# STM32WLE5_CM4 register map
File version: 1.0
CPU: CM4 r0p1, little endian, MPU, FPU, 4 interrupt priority bits
Registers are 32-bit, read-write, reset 0x0 unless marked. A register's access mark holds for its fields unless they carry their own. Offsets are from the block's base; [hi:lo] are bit positions; {n}, {i} and the like mark numbered series.

## VREFBUF — Voltage reference buffer
Base 0x40010030
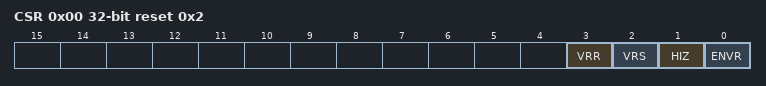
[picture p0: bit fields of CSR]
0x00 CSR access per field reset 0x2 — control and status register
  [3] VRR ro — Voltage reference buffer ready
  [2] VRS rw — Voltage reference scale
  [1] HIZ rw — High impedance mode
  [0] ENVR rw — Voltage reference buffer mode enable
0x04 CCR — calibration control register
  [5:0] TRIM — Trimming code

## IWDG — Independent watchdog
Base 0x40003000
0x00 KR wo — Key register
  [15:0] KEY — Key value (write only, read 0x0000)
0x04 PR reset 0x7 — Prescaler register
  [2:0] PR — Prescaler divider
0x08 RLR reset 0xFFF — Reload register
  [11:0] RL — Watchdog counter reload value
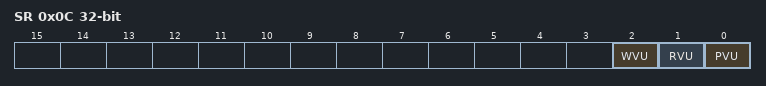
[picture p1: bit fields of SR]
0x0C SR ro — Status register
  [2] WVU — Watchdog counter window value update
  [1] RVU — Watchdog counter reload value update
  [0] PVU — Watchdog prescaler value update
0x10 WINR reset 0xFFF — Window register
  [11:0] WIN — Watchdog counter window value

## WWDG — System window watchdog
Base 0x40002C00
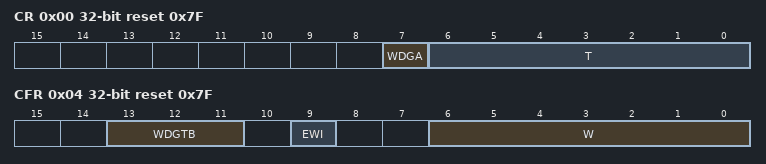
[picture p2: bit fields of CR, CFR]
0x00 CR reset 0x7F — Control register
  [7] WDGA — Activation bit
  [6:0] T — 7-bit counter (MSB to LSB)
0x04 CFR access per field reset 0x7F — Configuration register
  [13:11] WDGTB rw — Timer base
  [9] EWI wo — Early wakeup interrupt
  [6:0] W rw — 7-bit window value
0x08 SR — Status register
  [0] EWIF — Early wakeup interrupt flag

## AES — Advanced encryption standard hardware accelerator 1
Base 0x58001800
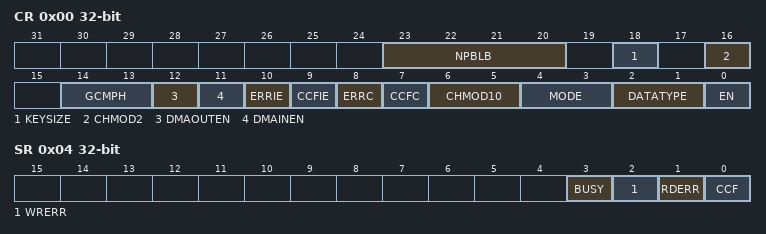
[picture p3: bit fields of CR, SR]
0x00 CR — control register
  [23:20] NPBLB — Number of padding bytes in last block of payload
  [18] KEYSIZE — Key size selection
  [16] CHMOD2 — AES chaining mode Bit2
  [14:13] GCMPH — Used only for GCM, CCM and GMAC algorithms and has no effect when other algorithms are selected
  [12] DMAOUTEN — Enable DMA management of data output phase
  [11] DMAINEN — Enable DMA management of data input phase
  [10] ERRIE — Error interrupt enable
  [9] CCFIE — CCF flag interrupt enable
  [8] ERRC — Error clear
  [7] CCFC — Computation Complete Flag Clear
  [6:5] CHMOD10 — AES chaining mode Bit1 Bit0
  [4:3] MODE — AES operating mode
  [2:1] DATATYPE — Data type selection (for data in and data out to/from the cryptographic block)
  [0] EN — AES enable
0x04 SR ro — status register
  [3] BUSY — Busy flag
  [2] WRERR — Write error flag
  [1] RDERR — Read error flag
  [0] CCF — Computation complete flag
0x08 DINR — data input register
  [31:0] AES_DINR — Data Input Register
0x0C DOUTR ro — data output register
  [31:0] AES_DOUTR — Data output register
0x10 KEYR0 wo — key register 0
  [31:0] AES_KEYR0 — Data Output Register (LSB key [31:0])
0x14 KEYR1 wo — key register 1
  [31:0] AES_KEYR1 — AES key register (key [63:32])
0x18 KEYR2 wo — key register 2
  [31:0] AES_KEYR2 — AES key register (key [95:64])
0x1C KEYR3 wo — key register 3
  [31:0] AES_KEYR3 — AES key register (MSB key [127:96])
0x20 IVR0 — initialization vector register 0
  [31:0] AES_IVR0 — initialization vector register (LSB IVR [31:0])
0x24 IVR1 — initialization vector register 1
  [31:0] AES_IVR1 — Initialization Vector Register (IVR [63:32])
0x28 IVR2 — initialization vector register 2
  [31:0] AES_IVR2 — Initialization Vector Register (IVR [95:64])
0x2C IVR3 — initialization vector register 3
  [31:0] AES_IVR3 — Initialization Vector Register (MSB IVR [127:96])
{0x20+4i} KEYR{i} wo (i=4..7) — key register {i}
  [31:0] AES_KEYR{i} — AES key register (MSB key [{32i+31}:{32i}])
{0x40+4i} SUSP{i}R (i=0..7) — AES suspend register {i}
  [31:0] AES_SUSP{i}R

## SPI1 — Serial peripheral interface/Inter-IC sound
Base 0x40013000
Same registers: SPI2 0x40003800, SPI3 0x58010000
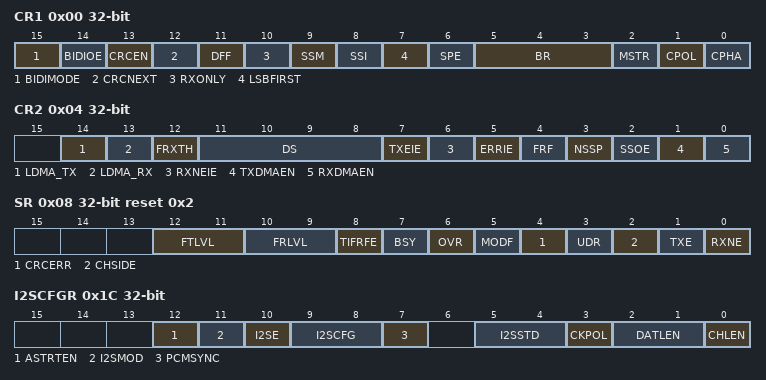
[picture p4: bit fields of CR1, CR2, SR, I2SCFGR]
0x00 CR1 — control register 1
  [15] BIDIMODE — Bidirectional data mode enable
  [14] BIDIOE — Output enable in bidirectional mode
  [13] CRCEN — Hardware CRC calculation enable
  [12] CRCNEXT — CRC transfer next
  [11] DFF — Data frame format
  [10] RXONLY — Receive only
  [9] SSM — Software slave management
  [8] SSI — Internal slave select
  [7] LSBFIRST — Frame format
  [6] SPE — SPI enable
  [5:3] BR — Baud rate control
  [2] MSTR — Master selection
  [1] CPOL — Clock polarity
  [0] CPHA — Clock phase
0x04 CR2 — control register 2
  [14] LDMA_TX — Last DMA transfer for transmission
  [13] LDMA_RX — Last DMA transfer for reception
  [12] FRXTH — FIFO reception threshold
  [11:8] DS — Data size
  [7] TXEIE — Tx buffer empty interrupt enable
  [6] RXNEIE — RX buffer not empty interrupt enable
  [5] ERRIE — Error interrupt enable
  [4] FRF — Frame format
  [3] NSSP — NSS pulse management
  [2] SSOE — SS output enable
  [1] TXDMAEN — Tx buffer DMA enable
  [0] RXDMAEN — Rx buffer DMA enable
0x08 SR access per field reset 0x2 — status register
  [12:11] FTLVL ro — FIFO transmission level
  [10:9] FRLVL ro — FIFO reception level
  [8] TIFRFE ro — TI frame format error
  [7] BSY ro — Busy flag
  [6] OVR ro — Overrun flag
  [5] MODF ro — Mode fault
  [4] CRCERR rw — CRC error flag
  [3] UDR ro
  [2] CHSIDE ro
  [1] TXE ro — Transmit buffer empty
  [0] RXNE ro — Receive buffer not empty
0x0C DR — data register
  [15:0] DR — Data register
0x10 CRCPR reset 0x7 — CRC polynomial register
  [15:0] CRCPOLY
0x14 RXCRCR ro — RX CRC register
  [15:0] RxCRC
0x18 TXCRCR ro — TX CRC register
  [15:0] TxCRC
0x1C I2SCFGR — configuration register
  [12] ASTRTEN, [11] I2SMOD, [10] I2SE, [9:8] I2SCFG, [7] PCMSYNC, [5:4] I2SSTD, [3] CKPOL, [2:1] DATLEN, [0] CHLEN
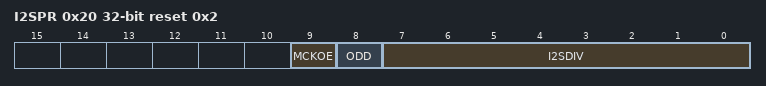
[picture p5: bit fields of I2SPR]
0x20 I2SPR reset 0x2 — prescaler register
  [9] MCKOE, [8] ODD, [7:0] I2SDIV
